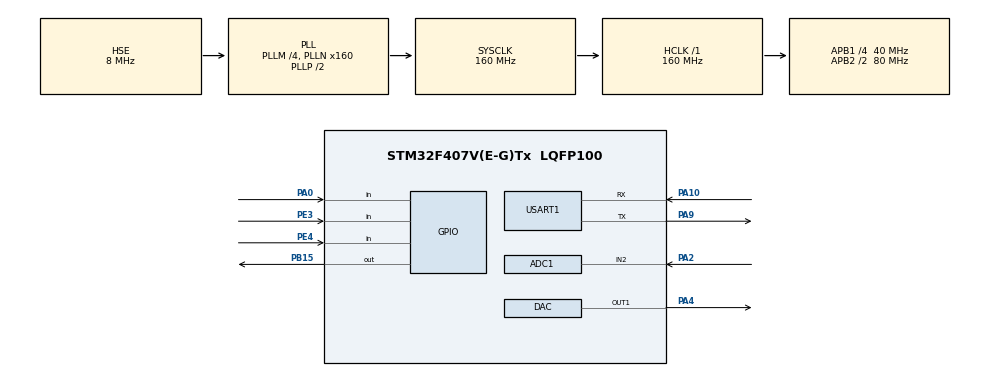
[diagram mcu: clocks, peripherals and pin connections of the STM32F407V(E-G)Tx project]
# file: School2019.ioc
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ADC1.Channel-3\#ChannelRegularConversion=ADC_CHANNEL_2
ADC1.NbrOfConversionFlag=1
ADC1.Rank-3\#ChannelRegularConversion=1
ADC1.SamplingTime-3\#ChannelRegularConversion=ADC_SAMPLETIME_3CYCLES
ADC1.master=1
DAC.DAC_Trigger=DAC_TRIGGER_T6_TRGO
Dma.DAC1.0.Direction=DMA_MEMORY_TO_PERIPH
Dma.DAC1.0.FIFOMode=DMA_FIFOMODE_DISABLE
Dma.DAC1.0.Instance=DMA1_Stream5
Dma.DAC1.0.MemDataAlignment=DMA_MDATAALIGN_HALFWORD
Dma.DAC1.0.MemInc=DMA_MINC_ENABLE
Dma.DAC1.0.Mode=DMA_NORMAL
Dma.DAC1.0.PeriphDataAlignment=DMA_PDATAALIGN_HALFWORD
Dma.DAC1.0.PeriphInc=DMA_PINC_DISABLE
Dma.DAC1.0.Priority=DMA_PRIORITY_LOW
Dma.Request0=DAC1
Mcu.Family=STM32F4
Mcu.Name=STM32F407V(E-G)Tx
Mcu.Package=LQFP100
NVIC.DMA1_Stream5_IRQn=true\:0\:0\:false\:false\:true\:false\:true
NVIC.PriorityGroup=NVIC_PRIORITYGROUP_4
PA0-WKUP.GPIO_PuPd=GPIO_NOPULL
PA0-WKUP.Signal=GPIO_Input
PA10.Mode=Asynchronous
PA10.Signal=USART1_RX
PA13.Mode=JTAG_4_pins
PA13.Signal=SYS_JTMS-SWDIO
PA14.Mode=JTAG_4_pins
PA14.Signal=SYS_JTCK-SWCLK
PA15.Mode=JTAG_4_pins
PA15.Signal=SYS_JTDI
PA2.Signal=ADCx_IN2
PA4.Signal=COMP_DAC1_group
PA9.Mode=Asynchronous
PA9.Signal=USART1_TX
PB15.GPIO_Speed=GPIO_SPEED_FREQ_VERY_HIGH
PB15.Signal=GPIO_Output
PB3.Mode=JTAG_4_pins
PB3.Signal=SYS_JTDO-SWO
PC14-OSC32_IN.Mode=LSE-External-Oscillator
PC14-OSC32_IN.Signal=RCC_OSC32_IN
PC15-OSC32_OUT.Mode=LSE-External-Oscillator
PC15-OSC32_OUT.Signal=RCC_OSC32_OUT
PE3.GPIO_PuPd=GPIO_PULLUP
PE3.Signal=GPIO_Input
PE4.GPIO_PuPd=GPIO_PULLUP
PE4.Signal=GPIO_Input
PH0-OSC_IN.Mode=HSE-External-Oscillator
PH0-OSC_IN.Signal=RCC_OSC_IN
PH1-OSC_OUT.Mode=HSE-External-Oscillator
PH1-OSC_OUT.Signal=RCC_OSC_OUT
ProjectManager.HeapSize=0x200
ProjectManager.StackSize=0xA000
ProjectManager.TargetToolchain=MDK-ARM V5
RCC.48MHZClocksFreq_Value=80000000
RCC.AHBFreq_Value=160000000
RCC.APB1CLKDivider=RCC_HCLK_DIV4
RCC.APB1Freq_Value=40000000
RCC.APB1TimFreq_Value=80000000
RCC.APB2CLKDivider=RCC_HCLK_DIV2
RCC.APB2Freq_Value=80000000
RCC.APB2TimFreq_Value=160000000
RCC.CortexFreq_Value=160000000
RCC.HCLKFreq_Value=160000000
RCC.HSE_VALUE=8000000
RCC.HSI_VALUE=16000000
RCC.PLLM=4
RCC.PLLN=160
RCC.PLLSourceVirtual=RCC_PLLSOURCE_HSE
RCC.SYSCLKFreq_VALUE=160000000
RCC.SYSCLKSource=RCC_SYSCLKSOURCE_PLLCLK
RCC.VCOOutputFreq_Value=320000000
SH.ADCx_IN2.0=ADC1_IN2,IN2
SH.COMP_DAC1_group.0=DAC_OUT1,DAC_OUT1
TIM3.Period=1
TIM3.Prescaler=20480
TIM3.TIM_MasterOutputTrigger=TIM_TRGO_UPDATE
TIM6.Period=1
TIM6.Prescaler=79
TIM6.TIM_MasterOutputTrigger=TIM_TRGO_UPDATE
USART1.VirtualMode=VM_ASYNC
VP_TIM3_VS_ClockSourceINT.Mode=Internal
VP_TIM6_VS_ClockSourceINT.Mode=Enable_Timer
board=custom

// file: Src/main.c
/* USER CODE BEGIN Header */
/**
  ******************************************************************************
  * @file           : main.c
  * @brief          : Main program body
  ******************************************************************************
  * @attention
  *
  * <h2><center>&copy; Copyright (c) 2019 STMicroelectronics.
  * All rights reserved.</center></h2>
  *
  * This software component is licensed by ST under BSD 3-Clause license,
  * the "License"; You may not use this file except in compliance with the
  * License. You may obtain a copy of the License at:
  *                        opensource.org/licenses/BSD-3-Clause
  *
  ******************************************************************************
  */
/* USER CODE END Header */

#include "main.h"
#include "adc.h"
#include "dac.h"
#include "dma.h"
#include "tim.h"
#include "usart.h"
#include "gpio.h"

/* USER CODE BEGIN Includes */
#include "User_main.h"
/* USER CODE END Includes */

/* USER CODE BEGIN PV */
/* Private variables ---------------------------------------------------------*/

/* USER CODE END PV */

void SystemClock_Config(void);
/* USER CODE BEGIN PFP */
/* Private function prototypes -----------------------------------------------*/

/* USER CODE END PFP */

int main(void)
{

  /* MCU Configuration--------------------------------------------------------*/

  /* Reset of all peripherals, Initializes the Flash interface and the Systick. */
  HAL_Init();

  /* Configure the system clock */
  SystemClock_Config();

  /* Initialize all configured peripherals */
  MX_GPIO_Init();
  MX_DMA_Init();
  MX_TIM3_Init();
  MX_USART1_UART_Init();
  MX_DAC_Init();
  MX_TIM6_Init();
  MX_ADC1_Init();

  /* Infinite loop */
  /* USER CODE BEGIN WHILE */
  while (1)
  {
		User_main();
    /* USER CODE END WHILE */

  }
}

void SystemClock_Config(void)
{
  RCC_OscInitTypeDef RCC_OscInitStruct = {0};
  RCC_ClkInitTypeDef RCC_ClkInitStruct = {0};

  /** Configure the main internal regulator output voltage
  */
  __HAL_RCC_PWR_CLK_ENABLE();
  __HAL_PWR_VOLTAGESCALING_CONFIG(PWR_REGULATOR_VOLTAGE_SCALE1);
  /** Initializes the CPU, AHB and APB busses clocks
  */
  RCC_OscInitStruct.OscillatorType = RCC_OSCILLATORTYPE_HSE;
  RCC_OscInitStruct.HSEState = RCC_HSE_ON;
  RCC_OscInitStruct.PLL.PLLState = RCC_PLL_ON;
  RCC_OscInitStruct.PLL.PLLSource = RCC_PLLSOURCE_HSE;
  RCC_OscInitStruct.PLL.PLLM = 4;
  RCC_OscInitStruct.PLL.PLLN = 160;
  RCC_OscInitStruct.PLL.PLLP = RCC_PLLP_DIV2;
  RCC_OscInitStruct.PLL.PLLQ = 4;
  if (HAL_RCC_OscConfig(&RCC_OscInitStruct) != HAL_OK)
  {
    Error_Handler();
  }
  /** Initializes the CPU, AHB and APB busses clocks
  */
  RCC_ClkInitStruct.ClockType = RCC_CLOCKTYPE_HCLK|RCC_CLOCKTYPE_SYSCLK
                              |RCC_CLOCKTYPE_PCLK1|RCC_CLOCKTYPE_PCLK2;
  RCC_ClkInitStruct.SYSCLKSource = RCC_SYSCLKSOURCE_PLLCLK;
  RCC_ClkInitStruct.AHBCLKDivider = RCC_SYSCLK_DIV1;
  RCC_ClkInitStruct.APB1CLKDivider = RCC_HCLK_DIV4;
  RCC_ClkInitStruct.APB2CLKDivider = RCC_HCLK_DIV2;

  if (HAL_RCC_ClockConfig(&RCC_ClkInitStruct, FLASH_LATENCY_5) != HAL_OK)
  {
    Error_Handler();
  }
}

void Error_Handler(void)
{
  while(1)
  {
  }
}

/************************ (C) COPYRIGHT STMicroelectronics *****END OF FILE****/
